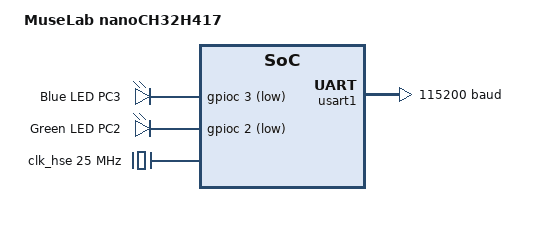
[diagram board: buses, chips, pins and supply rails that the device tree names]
/*
 * Copyright (c) 2026 Liu Changjie
 *
 * SPDX-License-Identifier: Apache-2.0
 */

/dts-v1/;

#include <wch/ch32h417/ch32h417_v5f.dtsi>
#include "nano_ch32h417-pinctrl.dtsi"
#include <zephyr/dt-bindings/gpio/gpio.h>

/ {
	model = "MuseLab nanoCH32H417";
	compatible = "muselab,nano-ch32h417";

	chosen {
		zephyr,sram = &sram0;
		zephyr,flash = &flash0;
		zephyr,console = &usart1;
		zephyr,shell-uart = &usart1;
	};

	leds {
		compatible = "gpio-leds";
		status = "okay";

		blue_led: led0 {
			gpios = <&gpioc 3 GPIO_ACTIVE_LOW>;
			label = "Blue LED PC3";
		};

		green_led: led1 {
			gpios = <&gpioc 2 GPIO_ACTIVE_LOW>;
			label = "Green LED PC2";
		};
	};

	aliases {
		led0 = &blue_led;
		led1 = &green_led;
	};
};

&gpioa {
	status = "okay";
};

&gpioc {
	status = "okay";
};

&clk_hse {
	clock-frequency = <DT_FREQ_M(25)>;
	status = "okay";
};

&pll {
	clocks = <&clk_hse>;
	status = "okay";
};

&rcc {
	clocks = <&pll>;
};

&usart1 {
	status = "okay";
	current-speed = <115200>;
	pinctrl-0 = <&usart1_default>;
	pinctrl-names = "default";
};
